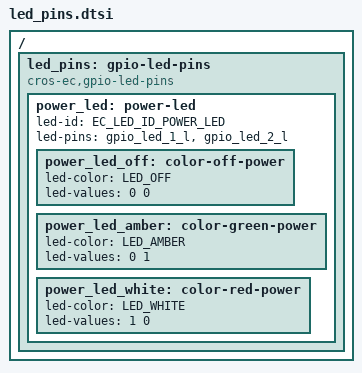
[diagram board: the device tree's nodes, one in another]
/* Copyright 2024 The ChromiumOS Authors
 * Use of this source code is governed by a BSD-style license that can be
 * found in the LICENSE file.
 */

/ {
	led_pins: gpio-led-pins {
		compatible = "cros-ec,gpio-led-pins";

		power_led: power-led {
			led-id = "EC_LED_ID_POWER_LED";
			led-pins = <&gpio_led_1_l &gpio_led_2_l>;
			power_led_off: color-off-power {
				led-color = "LED_OFF";
				led-values = <0 0>;
			};

			power_led_amber: color-green-power {
				led-color = "LED_AMBER";
				led-values = <0 1>;
			};

			power_led_white: color-red-power {
				led-color = "LED_WHITE";
				led-values = <1 0>;
			};
		};
	};
};
